# APM32F465 register map
File version: 1.0
CPU: CM4 r1p0, little endian, no MPU, no FPU, 3 interrupt priority bits
Registers are 32-bit, read-write, reset 0x0 unless marked. A register's access mark holds for its fields unless they carry their own. Offsets are from the block's base; [hi:lo] are bit positions; {n}, {i} and the like mark numbered series.

## OTG_FS_PWRCLK — USB on the go full speed
Base 0x50000E00
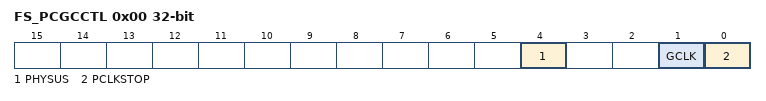
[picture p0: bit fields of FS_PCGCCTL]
0x00 FS_PCGCCTL — OTG_FS power and clock gating control register
  [4] PHYSUS — PHY Suspended
  [1] GCLK — Gate HCLK
  [0] PCLKSTOP — Stop PHY clock

## OTG_HS2 — USB on the go high speed
Base 0x40040200
0x00 USB_SWITCH
  [0] usb_switch
0x04 POWERON_CORE
  [0] poweron_core
0x08 USB_PLL_EN — USB PLL Enable
  [0] usb_pll_en
0x0C SHORT_5V_ENABLE — VBUS Short 5V Enable
  [0] short_5v_enable
0x10 OTG_SUSPENDM — OTG VBUS Suspend
  [0] otg_suspendm
0x14 TXBITSTUFFENABLE
  [0] txbitstuffenable
0x18 PLLICP_SEL_I2C — PLL charge current setting
  [0] pllicp_sel_i2c
0x1C HSZR_CNTL_I2C ro reset 0x4 — The DP/DM to the ground impedance setting
  [2:0] hszr_cntl_i2c
0x20 SQVTH_CNTL_I2C ro reset 0x1 — The SQ reference voltage setting
  [1:0] sqvth_cntl_i2c
0x24 SW_RREF_I2C ro reset 0x4 — The DP/DM output swing setting when HS mode
  [2:0] sw_rref_i2c
0x28 SW_BUF_I2C ro — The TX driver setting
  [0] sw_buf_i2c
0x2C TX2RX_T_CFG_I2C reset 0x2 — Debug control signal
  [1:0] tx2rx_t_cfg_i2c
0x30 TEST_ANA_FAST_I2C — Debug control signal
  [2:0] test_ana_fast_i2c
0x34 CLK_MODE_I2C — Debug control signal
  [2:0] clk_mode_i2c
0x38 USB_DBNCE_FLTR_BYPASS ro reset 0x80200 — Bypass debounce filters for avalid, bvalid, vbusvalid, sessend, iddig signals when enabled
  [0] usb_dbnce_fltr_bypass
0x3C USB_SS_SCALEDOWN_MODE — Used only in simulation
  [0] usb_ss_scaledown_mode

## OTG_HS1_PWRCLK — USB on the go high speed
Base 0x40040E00
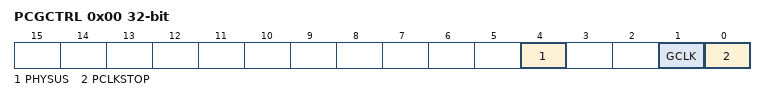
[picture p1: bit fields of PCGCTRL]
0x00 PCGCTRL — Power and clock gating control register
  [4] PHYSUS — PHY suspended
  [1] GCLK — Gate HCLK
  [0] PCLKSTOP — Stop PHY clock

## BN — Big number
Base 0x500A0000
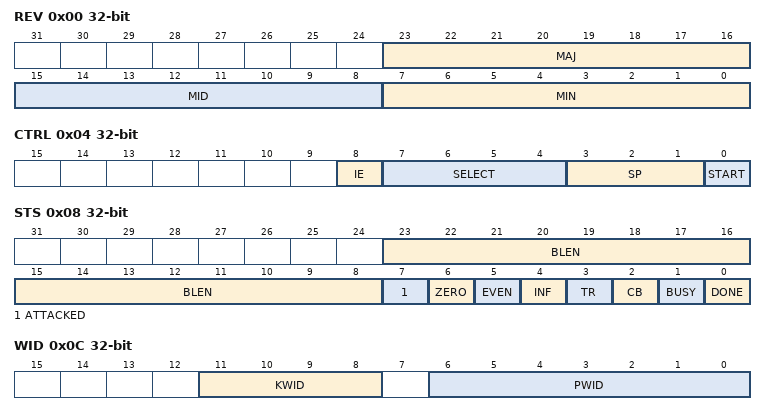
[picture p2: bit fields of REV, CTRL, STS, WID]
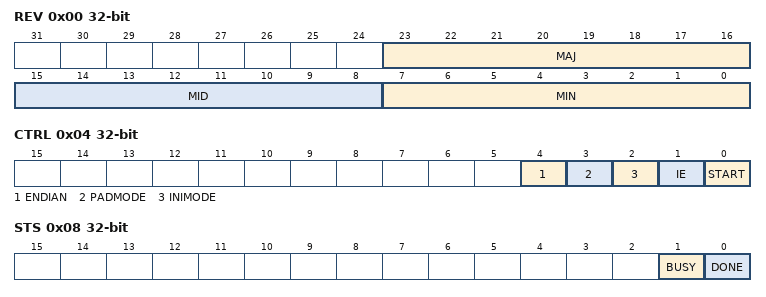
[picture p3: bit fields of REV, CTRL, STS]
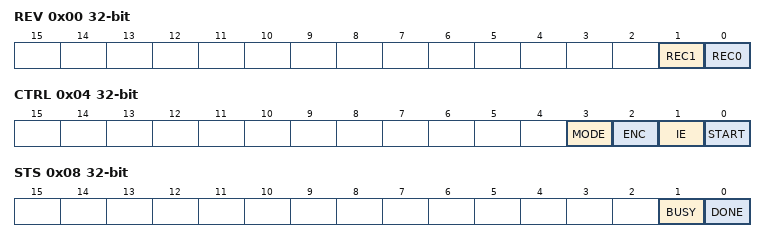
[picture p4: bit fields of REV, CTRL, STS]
0x00 REV ro — Revision Register
  [23:16] MAJ — Major revision.
  [15:8] MID — Middle revision.
  [7:0] MIN — Minor revision.
0x04 CTRL — control register
  [8] IE — Interrupt
  [7:4] SELECT
  [3:1] SP — Security parameter
  [0] START — Start a new operation.
0x08 STS — status register
  [23:8] BLEN — Bit length
  [7] ATTACKED
  [6] ZERO — B/K/M zero
  [5] EVEN — Modulo even
  [4] INF — Infinity point
  [3] TR — Test result
  [2] CB — Carry out or borrow in
  [1] BUSY — Operation is done
  [0] DONE — Operation is done
0x0C WID — Operand Width register
  [11:8] KWID — ECPM key width
  [6:0] PWID — ECPM P width
0x40 P — P/M register
  [31:0] P_REG — Write modulus P/M into IP
0x44 A — BN Operand/EC Parameter A register
  [31:0] A_REG — Write operand A or ECC parameter A into IP
0x48 B — BN Operand/EC Parameter B register
  [31:0] B_REG — Write operand B or ECC parameter B into IP
0x4C K — ECC Key register
  [31:0] K_REG — Write ECC key into IP
0x50 PX — ECC x coordinate of Point P
  [31:0] PX_REG — Write x coordinate of point P into IP
0x54 PY — ECC y coordinate of Point P
  [31:0] PY_REG — Write y coordinate of point P into IP
0x58 SX — ECC x coordinate of Point S
  [31:0] SX_REG — Write x coordinate of point S into IP
0x5C SY — ECC y coordinate of Point S
  [31:0] SY_REG — Write y coordinate of point S into IP
0x60 RX ro — ECC x coordinate of Point R
  [31:0] RX_REG — Read BN result R or ECC result x coordinate of point R from IP
0x64 RY ro — ECC y coordinate of Point R
  [31:0] RY_REG — Read ECC result y coordinate of point R from IP
0x68 RND wo — Random number register
  [31:0] RND_REG — Write a true random number to it

## SM3
Base 0x50080000
0x00 REV ro — Revision Register
  [23:16] MAJ — Major revision.
  [15:8] MID — Middle revision.
  [7:0] MIN — Minor revision.
0x04 CTRL — control register
  [4] ENDIAN — Endian mode in word
  [3] PADMODE — Hardware Padding mode
  [2] INIMODE — Hardware initialization Mode
  [1] IE — Interrupt
  [0] START — Start a new operation.
0x08 STS access per field — status register
  [1] BUSY ro — Operation is done
  [0] DONE rw — Operation is done
0x0C DILH wo — Data input length higher register
  [31:0] DATA — The length of input message higher 32 bits
0x10 DILL wo — Data input length lower register
  [31:0] DATA — The length of input message lower 32 bits
{0x14+4i} DIN{i} (i=0..15) — Input Message Register
  [31:0] DATA
{0x54+4i} IV{i} (i=0..7) — Input Initial Value
  [31:0] DATA
{0x74+4i} DOUT{i} ro (i=0..7) — Output Message Digest Register
  [31:0] DATA

## SM4
Base 0x50080400
0x00 REV ro — Revision Register
  [1] REC1 — Vision record
  [0] REC0 — Vision record
0x04 CTRL — control register
  [3] MODE — ECB/CBC mode
  [2] ENC — ncryption/Decryption operation
  [1] IE — Interrupt
  [0] START — Start a new operation.
0x08 STS access per field — status register
  [1] BUSY ro — Operation is done
  [0] DONE rw — Operation is done
{0xC+4i} KEY{i} (i=0..3) — key register
  [31:0] DATA
{0x1C+4i} DIN{i} (i=0..3) — Input Message Register
  [31:0] DATA
{0x2C+4i} DOUT{i} ro (i=0..3) — Output Message Digest Register
  [31:0] DATA
{0x3C+4i} IV{i} (i=0..3) — Initial vector register
  [31:0] DATA
